# moondancer register map
Vendor: luna-soc
Registers are 8-bit, read-write, reset 0x0 unless marked. A register's access mark holds for its fields unless they carry their own. Offsets are from the block's base; [hi:lo] are bit positions; <NAME> marks a mode.

## usb0_ep_out
Base 0xF0000B00
Same registers: usb1_ep_out 0xF0000F00, usb2_ep_out 0xF0001300
0x00 control — Control register address: Controls the current device's USB address. Should be written after a SET_ADDRESS request is received. Automatically resets back to zero on a USB reset.
  [7:0] address
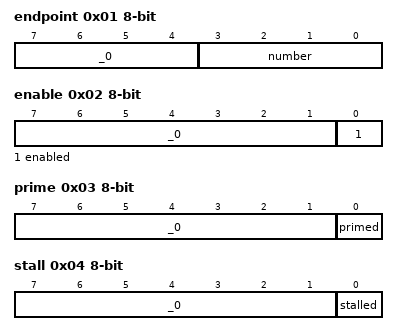
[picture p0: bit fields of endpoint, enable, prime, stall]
0x01 endpoint — Endpoint register number: Selects the endpoint number to prime. This interface allows priming multiple endpoints at once. That is, multiple endpoints can be ready to receive data at a time. See the `prime` and `enable` bits for usage.
  [7:4] _0, [3:0] number
0x02 enable — Enable register enabled: Controls whether any data can be received on any primed OUT endpoint. This bit is automatically cleared on receive in order to give the controller time to read data from the FIFO. It must be re-enabled once the FIFO has been emptied.
  [7:1] _0, [0] enabled wo
0x03 prime — Prime register primed: Controls "priming" an out endpoint. To receive data on any endpoint, the CPU must first select the endpoint with the `epno` register; and then write a '1' into the prime and enable register. This prepares our FIFO to receive data; and the next OUT transaction will be captured into the FIFO. When a transaction is complete, the `enable` bit is reset; the `prime` is not. This effectively means that `enable` controls receiving on _any_ of the primed endpoints; while `prime` can be used to build a collection of endpoints willing to participate in receipt. Note that this does not apply to the control endpoint. Once the control endpoint has received a packet it will be un-primed and need to be re-primed before it can receive again. This is to ensure that we can establish an order on the receipt of the setup packet and any associated data. Only one transaction / data packet is captured per `enable` write; repeated enabling is necessary to capture multiple packets.
  [7:1] _0, [0] primed wo
0x04 stall — Stall register stalled: Controls STALL'ing the active endpoint. Setting or clearing this bit will set or clear STALL on the provided endpoint. Endpoint STALLs persist even after `epno` is changed; so multiple endpoints can be stalled at once by writing their respective endpoint numbers into `epno` register and then setting their `stall` bits.
  [7:1] _0, [0] stalled wo
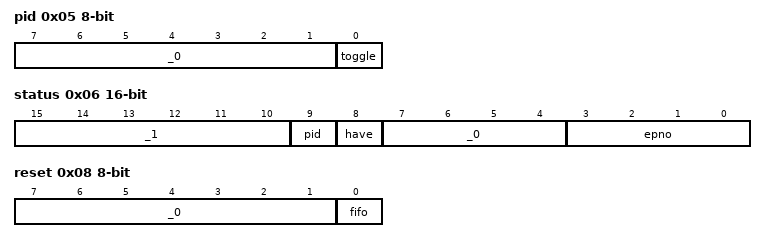
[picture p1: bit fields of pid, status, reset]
0x05 pid — Pid register toggle: Sets the current PID toggle bit for the given endpoint.
  [7:1] _0, [0] toggle wo
0x06 status 16-bit — Status register epno: Contains the endpoint number associated with the data in the FIFO -- that is, the endpoint number on which the relevant data was received. have: `1` iff data is available in the FIFO. pid: Contains the current PID toggle bit for the given endpoint.
  [15:10] _1, [9] pid ro, [8] have ro, [7:4] _0, [3:0] epno ro
0x08 reset — Reset register fifo: Local reset for the OUT handler; clears the out FIFO.
  [7:1] _0, [0] fifo wo
0x09 data — Data register Read-only register. A FIFO that returns the bytes from the most recently captured OUT transaction. Reading a byte from this register advances the FIFO. byte: Contains the most recently received byte.
  [7:0] byte ro
0x20 ev_enable — A CSR register. Parameters ---------- fields : :class:`dict` or :class:`list` or :class:`Field` Collection of register fields. If ``None`` (default), a dict is populated from Python :term:`variable annotations <python:variable annotations>`. ``fields`` is used to create a :class:`FieldActionMap`, :class:`FieldActionArray`, or :class:`FieldAction`, depending on its type (dict, list, or Field). Interface attributes -------------------- element : :class:`Element` Interface between this register and a CSR bus primitive. Attributes ---------- field : :class:`FieldActionMap` or :class:`FieldActionArray` or :class:`FieldAction` Collection of field instances. f : :class:`FieldActionMap` or :class:`FieldActionArray` or :class:`FieldAction` Shorthand for :attr:`Register.field`. Raises ------ :exc:`TypeError` If ``fields`` is neither ``None``, a :class:`dict`, a :class:`list`, or a :class:`Field`. :exc:`ValueError` If ``fields`` is not ``None`` and at least one variable annotation is a :class:`Field`. :exc:`ValueError` If ``element.access`` is not readable and at least one field is readable. :exc:`ValueError` If ``element.access`` is not writable and at least one field is writable.
  [0] mask
0x21 ev_pending — A CSR register. Parameters ---------- fields : :class:`dict` or :class:`list` or :class:`Field` Collection of register fields. If ``None`` (default), a dict is populated from Python :term:`variable annotations <python:variable annotations>`. ``fields`` is used to create a :class:`FieldActionMap`, :class:`FieldActionArray`, or :class:`FieldAction`, depending on its type (dict, list, or Field). Interface attributes -------------------- element : :class:`Element` Interface between this register and a CSR bus primitive. Attributes ---------- field : :class:`FieldActionMap` or :class:`FieldActionArray` or :class:`FieldAction` Collection of field instances. f : :class:`FieldActionMap` or :class:`FieldActionArray` or :class:`FieldAction` Shorthand for :attr:`Register.field`. Raises ------ :exc:`TypeError` If ``fields`` is neither ``None``, a :class:`dict`, a :class:`list`, or a :class:`Field`. :exc:`ValueError` If ``fields`` is not ``None`` and at least one variable annotation is a :class:`Field`. :exc:`ValueError` If ``element.access`` is not readable and at least one field is readable. :exc:`ValueError` If ``element.access`` is not writable and at least one field is writable.
  [0] mask
